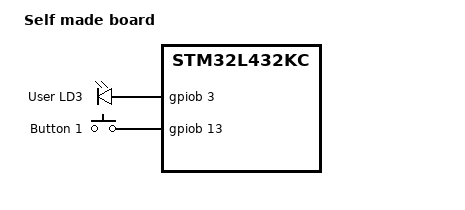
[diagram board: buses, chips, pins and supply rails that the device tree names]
// This line informs about device tree version
/dts-v1/; 
// The next two files are SoC support headers.
#include <st/l4/stm32l432Xc.dtsi>
#include <st/l4/stm32l432k(b-c)ux-pinctrl.dtsi>

/ {
    model = "Self made board";
    compatible = "st,stm32l432kc-nucleo";

    chosen {
        zephyr,console = &usart2;
        zephyr,shell-uart = &usart2;
        zephyr,sram = &sram0;
        zephyr,flash = &flash0;
        zephyr,can-primary = &can1;
    };

    leds {
        compatible = "gpio-leds";
        green_led: led_0 {
            gpios = <&gpiob 3 GPIO_ACTIVE_HIGH>;
            label = "User LD3";
        };
    };

    buttons {
        compatible = "gpio-keys";
        button1: button_1 {
            gpios = <&gpiob 13 (GPIO_PULL_DOWN | GPIO_ACTIVE_HIGH)>;
            label = "Button 1";
        };
    };

    aliases {
        led0 = &green_led;
        button1 = &button1;
    };
};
